# nrf52820 register map
Vendor: Nordic Semiconductor; Series: nrf52; File version: 1
CPU: CM4 r0p1, little endian, MPU, no FPU, 3 interrupt priority bits
Registers are 32-bit, read-write, reset 0x0 unless marked. A register's access mark holds for its fields unless they carry their own. Offsets are from the block's base; [hi:lo] are bit positions; {n}, {i} and the like mark numbered series.

## WDT — Watchdog Timer
Base 0x40010000
0x00 TASKS_START wo — Start the watchdog
  [0] TASKS_START
    1=Trigger task
0x100 EVENTS_TIMEOUT — Watchdog timeout
  [0] EVENTS_TIMEOUT
    0=NotGenerated (Event not generated); 1=Generated (Event generated)
0x304 INTENSET — Enable interrupt
  [0] TIMEOUT — Write '1' to enable interrupt for event TIMEOUT
    on read: 0=Disabled (Read: Disabled); 1=Enabled (Read: Enabled) | on write: 1=Set (Enable)
0x308 INTENCLR — Disable interrupt
  [0] TIMEOUT — Write '1' to disable interrupt for event TIMEOUT
    on read: 0=Disabled (Read: Disabled); 1=Enabled (Read: Enabled) | on write: 1=Clear (Disable)
0x400 RUNSTATUS ro
  [0] RUNSTATUS — Indicates whether or not the watchdog is running
    0=NotRunning (Watchdog not running); 1=Running (Watchdog is running)
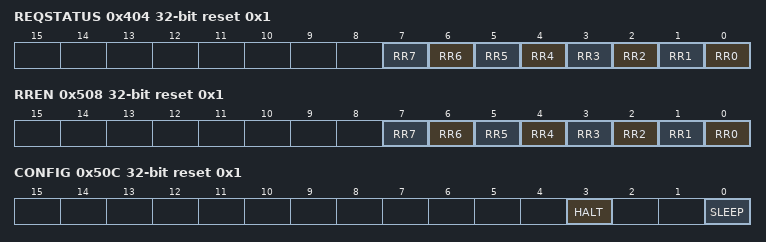
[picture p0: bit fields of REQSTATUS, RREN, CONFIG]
0x404 REQSTATUS ro reset 0x1 — Request status
  [n] RR{n} (n=0..7) — Request status for RR[{n}] register
    0=DisabledOrRequested (RR[{n}] register is not enabled, or are already requesting reload); 1=EnabledAndUnrequested (RR[{n}] register is enabled, and are not yet requesting reload)
0x504 CRV reset 0xFFFFFFFF — Counter reload value
  [31:0] CRV — Counter reload value in number of cycles of the 32.768 kHz clock
0x508 RREN reset 0x1 — Enable register for reload request registers
  [n] RR{n} (n=0..7) — Enable or disable RR[{n}] register
    0=Disabled (Disable RR[{n}] register); 1=Enabled (Enable RR[{n}] register)
0x50C CONFIG reset 0x1 — Configuration register
  [3] HALT — Configure the watchdog to either be paused, or kept running, while the CPU is halted by the debugger
    0=Pause watchdog while the CPU is halted by the debugger; 1=Run (Keep the watchdog running while the CPU is halted by the debugger)
  [0] SLEEP — Configure the watchdog to either be paused, or kept running, while the CPU is sleeping
    0=Pause watchdog while the CPU is sleeping; 1=Run (Keep the watchdog running while the CPU is sleeping)
{0x600+4i} RR[{i}] (i=0..7) wo — Description collection: Reload request n
  [31:0] RR — Reload request register
    0x6E524635=Reload (Value to request a reload of the watchdog timer)

## EGU0 — Event generator unit 0
Base 0x40014000
Same registers: EGU1 0x40015000, EGU2 0x40016000, EGU3 0x40017000, EGU4 0x40018000, EGU5 0x40019000
{0x0+4i} TASKS_TRIGGER[{i}] (i=0..15) wo — Description collection: Trigger n for triggering the corresponding TRIGGERED[n] event
  [0] TASKS_TRIGGER — Trigger n for triggering the corresponding TRIGGERED[n] event
    1=Trigger task
{0x100+4i} EVENTS_TRIGGERED[{i}] (i=0..15) — Description collection: Event number n generated by triggering the corresponding TRIGGER[n] task
  [0] EVENTS_TRIGGERED — Event number n generated by triggering the corresponding TRIGGER[n] task
    0=NotGenerated (Event not generated); 1=Generated (Event generated)
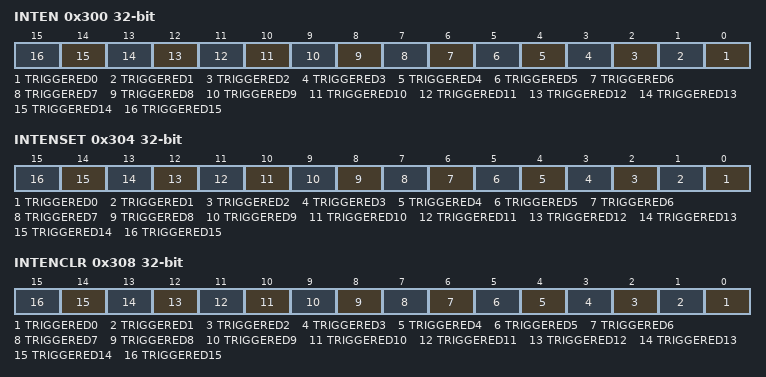
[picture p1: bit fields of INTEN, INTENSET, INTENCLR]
0x300 INTEN — Enable or disable interrupt
  [all] fields
    0=Disabled; 1=Enabled
  [n] TRIGGERED{n} (n=0..15) — Enable or disable interrupt for event TRIGGERED[{n}]
0x304 INTENSET — Enable interrupt
  [all] fields
    on read: 0=Disabled (Read: Disabled); 1=Enabled (Read: Enabled) | on write: 1=Set (Enable)
  [n] TRIGGERED{n} (n=0..15) — Write '1' to enable interrupt for event TRIGGERED[{n}]
0x308 INTENCLR — Disable interrupt
  [all] fields
    on read: 0=Disabled (Read: Disabled); 1=Enabled (Read: Enabled) | on write: 1=Clear (Disable)
  [n] TRIGGERED{n} (n=0..15) — Write '1' to disable interrupt for event TRIGGERED[{n}]

## SWI0 — Software interrupt 0
Base 0x40014000; alternate view of EGU0
Same registers: SWI1 0x40015000 (alternate view of EGU1), SWI2 0x40016000 (alternate view of EGU2), SWI3 0x40017000 (alternate view of EGU3), SWI4 0x40018000 (alternate view of EGU4), SWI5 0x40019000 (alternate view of EGU5)
